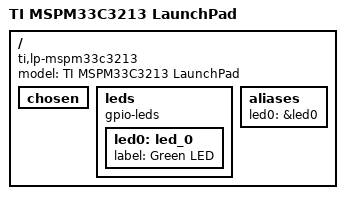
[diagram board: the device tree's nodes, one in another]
// SPDX-License-Identifier: Apache-2.0

/dts-v1/;

// TODO: add SoC include once mspm33c3213.dtsi is available in hal/ti
// #include <ti/mspm33/mspm33c3213.dtsi>

/ {
	model = "TI MSPM33C3213 LaunchPad";
	compatible = "ti,lp-mspm33c3213";

	chosen {
		// zephyr,sram = &sram0;
		// zephyr,flash = &flash0;
		// zephyr,console = &uart0;
	};

	leds {
		compatible = "gpio-leds";
		led0: led_0 {
			// TODO: fill in correct GPIO pin when DTS is available
			// gpios = <&gpioa 0 GPIO_ACTIVE_HIGH>;
			label = "Green LED";
		};
	};

	aliases {
		led0 = &led0;
	};
};
